# core register map
Vendor: litex
Registers are 32-bit, read-write, reset 0x0 unless marked. A register's access mark holds for its fields unless they carry their own. Offsets are from the block's base; [hi:lo] are bit positions; {n}, {i} and the like mark numbered series.

## IRQARRAY5
Base 0xE0013000
0x00 EV_SOFT — Software interrupt trigger register. ) Bits set to `1` will trigger an interrupt. Interrupts trigger on write, but the value will persist in the register, allowing software to determine if a software interrupt was triggered by reading back the register. Software is responsible for clearing the register to 0. Repeated `1` writes without clearing will still trigger an interrupt.
  [15:0] trigger
0x04 EV_EDGE_TRIGGERED — If a bit is set to 1, then the hardware trigger is edge-triggered
  [15:0] use_edge
0x08 EV_POLARITY — If a bit is set to 1, then the polarity is rising edge triggered; 0 is falling edge triggered. Bit is ignored if `edge_triggered` is 0.
  [15:0] rising
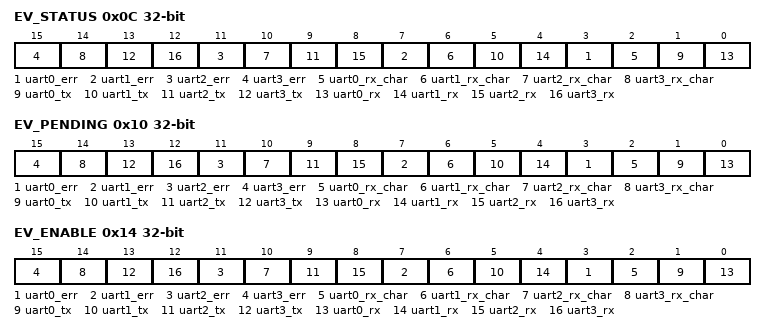
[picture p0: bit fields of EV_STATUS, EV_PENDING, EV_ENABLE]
0x0C EV_STATUS — `1` when a "uart3_err" event occurs. This event uses an `EventSourceFlex` form of triggering
  [4n+3] uart{n}_err (n=0..3) — Level of the ``uart{n}_err`` event
  [4n+2] uart{n}_rx_char (n=0..3) — Level of the ``uart{n}_rx_char`` event
  [4n+1] uart{n}_tx (n=0..3) — Level of the ``uart{n}_tx`` event
  [4n] uart{n}_rx (n=0..3) — Level of the ``uart{n}_rx`` event
0x10 EV_PENDING — `1` when a "uart3_err" event occurs. This event uses an `EventSourceFlex` form of triggering
  [4n+3] uart{n}_err (n=0..3) — `1` when a "uart{n}_err" event occurs. This event uses an `EventSourceFlex` form of triggering
  [4n+2] uart{n}_rx_char (n=0..3) — `1` when a "uart{n}_rx_char" event occurs. This event uses an `EventSourceFlex` form of triggering
  [4n+1] uart{n}_tx (n=0..3) — `1` when a "uart{n}_tx" event occurs. This event uses an `EventSourceFlex` form of triggering
  [4n] uart{n}_rx (n=0..3) — `1` when a "uart{n}_rx" event occurs. This event uses an `EventSourceFlex` form of triggering
0x14 EV_ENABLE — `1` when a "uart3_err" event occurs. This event uses an `EventSourceFlex` form of triggering
  [4n+3] uart{n}_err (n=0..3) — Write a ``1`` to enable the ``uart{n}_err`` Event
  [4n+2] uart{n}_rx_char (n=0..3) — Write a ``1`` to enable the ``uart{n}_rx_char`` Event
  [4n+1] uart{n}_tx (n=0..3) — Write a ``1`` to enable the ``uart{n}_tx`` Event
  [4n] uart{n}_rx (n=0..3) — Write a ``1`` to enable the ``uart{n}_rx`` Event

## IRQARRAY6
Base 0xE0014000
0x00 EV_SOFT — Software interrupt trigger register. ) Bits set to `1` will trigger an interrupt. Interrupts trigger on write, but the value will persist in the register, allowing software to determine if a software interrupt was triggered by reading back the register. Software is responsible for clearing the register to 0. Repeated `1` writes without clearing will still trigger an interrupt.
  [15:0] trigger
0x04 EV_EDGE_TRIGGERED — If a bit is set to 1, then the hardware trigger is edge-triggered
  [15:0] use_edge
0x08 EV_POLARITY — If a bit is set to 1, then the polarity is rising edge triggered; 0 is falling edge triggered. Bit is ignored if `edge_triggered` is 0.
  [15:0] rising
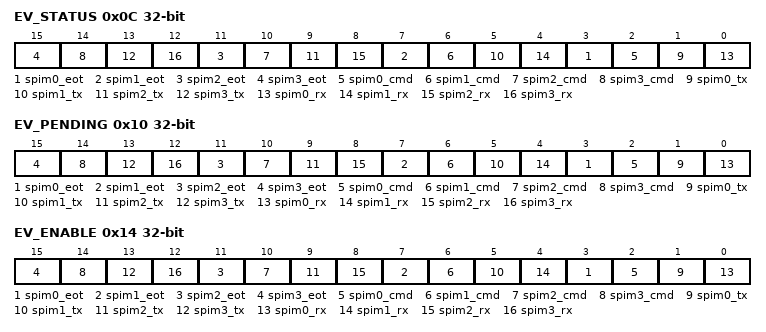
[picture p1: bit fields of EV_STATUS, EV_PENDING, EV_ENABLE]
0x0C EV_STATUS — `1` when a "spim3_eot" event occurs. This event uses an `EventSourceFlex` form of triggering
  [4n+3] spim{n}_eot (n=0..3) — Level of the ``spim{n}_eot`` event
  [4n+2] spim{n}_cmd (n=0..3) — Level of the ``spim{n}_cmd`` event
  [4n+1] spim{n}_tx (n=0..3) — Level of the ``spim{n}_tx`` event
  [4n] spim{n}_rx (n=0..3) — Level of the ``spim{n}_rx`` event
0x10 EV_PENDING — `1` when a "spim3_eot" event occurs. This event uses an `EventSourceFlex` form of triggering
  [4n+3] spim{n}_eot (n=0..3) — `1` when a "spim{n}_eot" event occurs. This event uses an `EventSourceFlex` form of triggering
  [4n+2] spim{n}_cmd (n=0..3) — `1` when a "spim{n}_cmd" event occurs. This event uses an `EventSourceFlex` form of triggering
  [4n+1] spim{n}_tx (n=0..3) — `1` when a "spim{n}_tx" event occurs. This event uses an `EventSourceFlex` form of triggering
  [4n] spim{n}_rx (n=0..3) — `1` when a "spim{n}_rx" event occurs. This event uses an `EventSourceFlex` form of triggering
0x14 EV_ENABLE — `1` when a "spim3_eot" event occurs. This event uses an `EventSourceFlex` form of triggering
  [4n+3] spim{n}_eot (n=0..3) — Write a ``1`` to enable the ``spim{n}_eot`` Event
  [4n+2] spim{n}_cmd (n=0..3) — Write a ``1`` to enable the ``spim{n}_cmd`` Event
  [4n+1] spim{n}_tx (n=0..3) — Write a ``1`` to enable the ``spim{n}_tx`` Event
  [4n] spim{n}_rx (n=0..3) — Write a ``1`` to enable the ``spim{n}_rx`` Event
